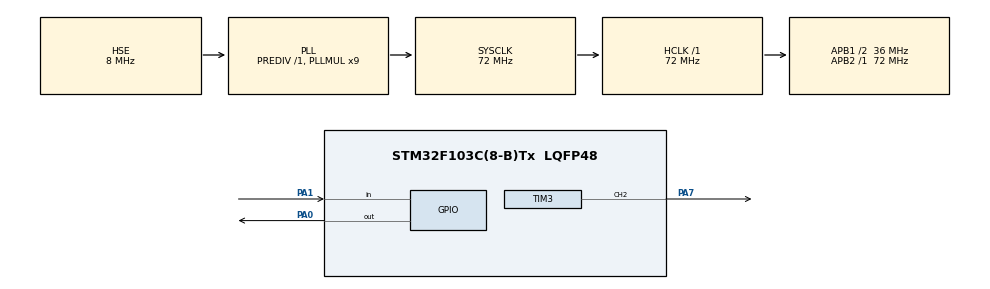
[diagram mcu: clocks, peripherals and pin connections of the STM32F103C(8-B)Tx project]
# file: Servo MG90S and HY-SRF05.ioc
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Mcu.Family=STM32F1
Mcu.Name=STM32F103C(8-B)Tx
Mcu.Package=LQFP48
NVIC.PriorityGroup=NVIC_PRIORITYGROUP_4
PA0-WKUP.Signal=GPIO_Output
PA1.GPIO_PuPd=GPIO_PULLDOWN
PA1.Signal=GPIO_Input
PA13.Mode=Trace_Asynchronous_SW
PA13.Signal=SYS_JTMS-SWDIO
PA14.Mode=Trace_Asynchronous_SW
PA14.Signal=SYS_JTCK-SWCLK
PA7.Signal=S_TIM3_CH2
PB3.Mode=Trace_Asynchronous_SW
PB3.Signal=SYS_JTDO-TRACESWO
PD0-OSC_IN.Mode=HSE-External-Oscillator
PD0-OSC_IN.Signal=RCC_OSC_IN
PD1-OSC_OUT.Mode=HSE-External-Oscillator
PD1-OSC_OUT.Signal=RCC_OSC_OUT
ProjectManager.HeapSize=0x200
ProjectManager.StackSize=0x400
ProjectManager.TargetToolchain=STM32CubeIDE
RCC.AHBFreq_Value=72000000
RCC.APB1CLKDivider=RCC_HCLK_DIV2
RCC.APB1Freq_Value=36000000
RCC.APB1TimFreq_Value=72000000
RCC.APB2Freq_Value=72000000
RCC.APB2TimFreq_Value=72000000
RCC.HCLKFreq_Value=72000000
RCC.PLLMUL=RCC_PLL_MUL9
RCC.PLLSourceVirtual=RCC_PLLSOURCE_HSE
RCC.SYSCLKFreq_VALUE=72000000
RCC.SYSCLKSource=RCC_SYSCLKSOURCE_PLLCLK
RCC.USBFreq_Value=72000000
SH.S_TIM3_CH2.0=TIM3_CH2,PWM Generation2 CH2
TIM3.Channel-PWM\ Generation2\ CH2=TIM_CHANNEL_2
TIM3.OCPolarity_2=TIM_OCPOLARITY_LOW
TIM3.Period=19999
TIM3.Prescaler=71
TIM3.Pulse-PWM\ Generation2\ CH2=1500
board=custom

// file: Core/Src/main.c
/* USER CODE BEGIN Header */
/**
  ******************************************************************************
  * @file           : main.c
  * @brief          : Distance-based servo control using STM32 and HC-SR04
  ******************************************************************************
  * @copyright      : MIT License (see LICENSE file in the root of the repository)
  * @date           : 2025
  ******************************************************************************
  */

/* USER CODE END Header */
#include "main.h"
#include "tim.h"
#include "gpio.h"

/* USER CODE BEGIN Includes */
#include "stdio.h"
#include <stdlib.h>
// Pin definitions for ultrasonic sensor
#define TRIG_PIN GPIO_PIN_0
#define TRIG_PORT GPIOA
#define ECHO_PIN GPIO_PIN_1
#define ECHO_PORT GPIOA
#define TIMEOUT_CYCLES (SystemCoreClock / 10) // ~100 ms
/* USER CODE END Includes */

void SystemClock_Config(void);
/* USER CODE BEGIN PFP */

/* Global variables -----------------------------------------------*/
float distance;
char buffer[16];
uint32_t pwm_value;
uint32_t lastUltraSonicSensorUpdate = 0;

// Initialize DWT for microsecond delays
void DWT_Delay_Init(void) {
    CoreDebug->DEMCR |= CoreDebug_DEMCR_TRCENA_Msk;
    DWT->CYCCNT = 0;
    DWT->CTRL |= DWT_CTRL_CYCCNTENA_Msk;
}

// Microsecond delay using DWT
void DWT_Delay_us(uint32_t us) {
    uint32_t start = DWT->CYCCNT;
    uint32_t delay = us * (SystemCoreClock / 1000000);
    while ((DWT->CYCCNT - start) < delay);
}

// Function to get distance using HY-SRF05 ultrasonic sensor + anti-freeze protection
float GetDistance(void) {
    uint32_t duration;

    HAL_GPIO_WritePin(TRIG_PORT, TRIG_PIN, GPIO_PIN_RESET);
    DWT_Delay_us(2);
    HAL_GPIO_WritePin(TRIG_PORT, TRIG_PIN, GPIO_PIN_SET);
    DWT_Delay_us(10);
    HAL_GPIO_WritePin(TRIG_PORT, TRIG_PIN, GPIO_PIN_RESET);

    uint32_t timeout = DWT->CYCCNT + TIMEOUT_CYCLES;
    while (HAL_GPIO_ReadPin(ECHO_PORT, ECHO_PIN) == GPIO_PIN_RESET) {
        if (DWT->CYCCNT > timeout) return -1;  // Error: no echo
    }

    uint32_t startTime = DWT->CYCCNT;
    timeout = DWT->CYCCNT + TIMEOUT_CYCLES;
    while (HAL_GPIO_ReadPin(ECHO_PORT, ECHO_PIN) == GPIO_PIN_SET) {
        if (DWT->CYCCNT > timeout) return -1;  // Error: echo too long
    }
    uint32_t endTime = DWT->CYCCNT;

    duration = endTime - startTime;
    return (duration / (SystemCoreClock / 1000000)) * 0.0343f / 2.0f;
}

// The median filter
float GetFilteredDistance(void)
{
    const int samples = 5;
    float values[samples];

    for (int i = 0; i < samples; i++) {
        values[i] = GetDistance();
        HAL_Delay(10);  // a short pause between measurements
    }

    // Sorting an array
    for (int i = 0; i < samples - 1; i++) {
        for (int j = i + 1; j < samples; j++) {
            if (values[i] > values[j]) {
                float tmp = values[i];
                values[i] = values[j];
                values[j] = tmp;
            }
        }
    }

    // Return the average value
    return values[samples / 2];
}

/* USER CODE END PFP */

int main(void)
{

  /* MCU Configuration--------------------------------------------------------*/

  /* Reset of all peripherals, Initializes the Flash interface and the Systick. */
  HAL_Init();

  /* Configure the system clock */
  SystemClock_Config();

  /* Initialize all configured peripherals */
  MX_GPIO_Init();
  MX_TIM3_Init();
  /* USER CODE BEGIN 2 */
  DWT_Delay_Init();
  HAL_TIM_PWM_Start(&htim3, TIM_CHANNEL_2);

  /* USER CODE END 2 */

  /* Infinite loop */
  /* USER CODE BEGIN WHILE */
  while (1)
  {
	  // Measure distance in centimeters
      distance = GetFilteredDistance();

      // Clamp distance within valid range
      if (distance > 50) distance = 50;
      if (distance < 0) distance = 0;

      // Map distance to PWM: 1300–1700us (safe range for continuous servo)
      pwm_value = 1500 + ((int)(distance - 25) * 4);  // -25..+25 → -50..+50

      // Update PWM duty cycle
      __HAL_TIM_SET_COMPARE(&htim3, TIM_CHANNEL_2, pwm_value);

      // Delay for stability
      HAL_Delay(100);
  }

  /* USER CODE END 3 */
}

// System clock configuration (generated by STM32CubeMX)
void SystemClock_Config(void)
{
  RCC_OscInitTypeDef RCC_OscInitStruct = {0};
  RCC_ClkInitTypeDef RCC_ClkInitStruct = {0};

  /** Initializes the RCC Oscillators according to the specified parameters
  * in the RCC_OscInitTypeDef structure.
  */
  RCC_OscInitStruct.OscillatorType = RCC_OSCILLATORTYPE_HSE;
  RCC_OscInitStruct.HSEState = RCC_HSE_ON;
  RCC_OscInitStruct.HSEPredivValue = RCC_HSE_PREDIV_DIV1;
  RCC_OscInitStruct.HSIState = RCC_HSI_ON;
  RCC_OscInitStruct.PLL.PLLState = RCC_PLL_ON;
  RCC_OscInitStruct.PLL.PLLSource = RCC_PLLSOURCE_HSE;
  RCC_OscInitStruct.PLL.PLLMUL = RCC_PLL_MUL9;
  if (HAL_RCC_OscConfig(&RCC_OscInitStruct) != HAL_OK)
  {
    Error_Handler();
  }

  /** Initializes the CPU, AHB and APB buses clocks
  */
  RCC_ClkInitStruct.ClockType = RCC_CLOCKTYPE_HCLK|RCC_CLOCKTYPE_SYSCLK
                              |RCC_CLOCKTYPE_PCLK1|RCC_CLOCKTYPE_PCLK2;
  RCC_ClkInitStruct.SYSCLKSource = RCC_SYSCLKSOURCE_PLLCLK;
  RCC_ClkInitStruct.AHBCLKDivider = RCC_SYSCLK_DIV1;
  RCC_ClkInitStruct.APB1CLKDivider = RCC_HCLK_DIV2;
  RCC_ClkInitStruct.APB2CLKDivider = RCC_HCLK_DIV1;

  if (HAL_RCC_ClockConfig(&RCC_ClkInitStruct, FLASH_LATENCY_2) != HAL_OK)
  {
    Error_Handler();
  }
}

void Error_Handler(void)
{
  __disable_irq();
  while (1)
  {
  }
}
